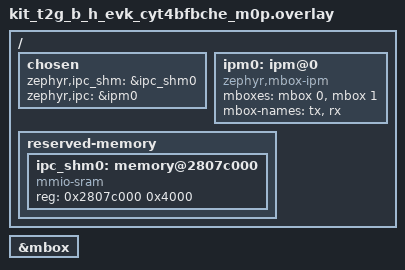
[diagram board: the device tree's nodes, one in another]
/*
 * Copyright (c) 2026 Infineon Technologies AG
 * SPDX-License-Identifier: Apache-2.0
 *
 * OpenAMP IPC overlay for kit_t2g_b_h_evk (CYT4BFBCHE) - Host (CM0P) with CM7_0 remote
 *
 * CURRENTLY CONFIGURED FOR: M0P ↔ M7_0
 *
 * To switch to M7_1 remote:
 * 1. In Kconfig.sysbuild, change:
 *    default "kit_t2g_b_h_evk/cyt4bfbche/m7_1" if $(BOARD) = "kit_t2g_b_h_evk/cyt4bfbche/m0p"
 * 2. Copy content from kit_t2g_b_h_evk_cyt4bfbche_m0p_for_m7_1.overlay to this file
 */

/ {
	chosen {
		zephyr,ipc_shm = &ipc_shm0;
		zephyr,ipc = &ipm0;
	};

	ipm0: ipm@0 {
		compatible = "zephyr,mbox-ipm";
		mboxes = <&mbox 0>, <&mbox 1>;
		mbox-names = "tx", "rx";
		status = "okay";
	};

	reserved-memory {
		#address-cells = <1>;
		#size-cells = <1>;

		/*
		 * Shared memory region for IPC between CM0P and CM7_1
		 * Located at the end of sram_m7_0 region
		 * Address: 0x2803C000 (M7_0 end - 16KB)
		 * Size: 16KB (0x4000)
		 */
		ipc_shm0: memory@2807c000 {
			compatible = "mmio-sram";
			reg = <0x2807c000 0x4000>;
		};
	};
};

&mbox {
	status = "okay";
};


